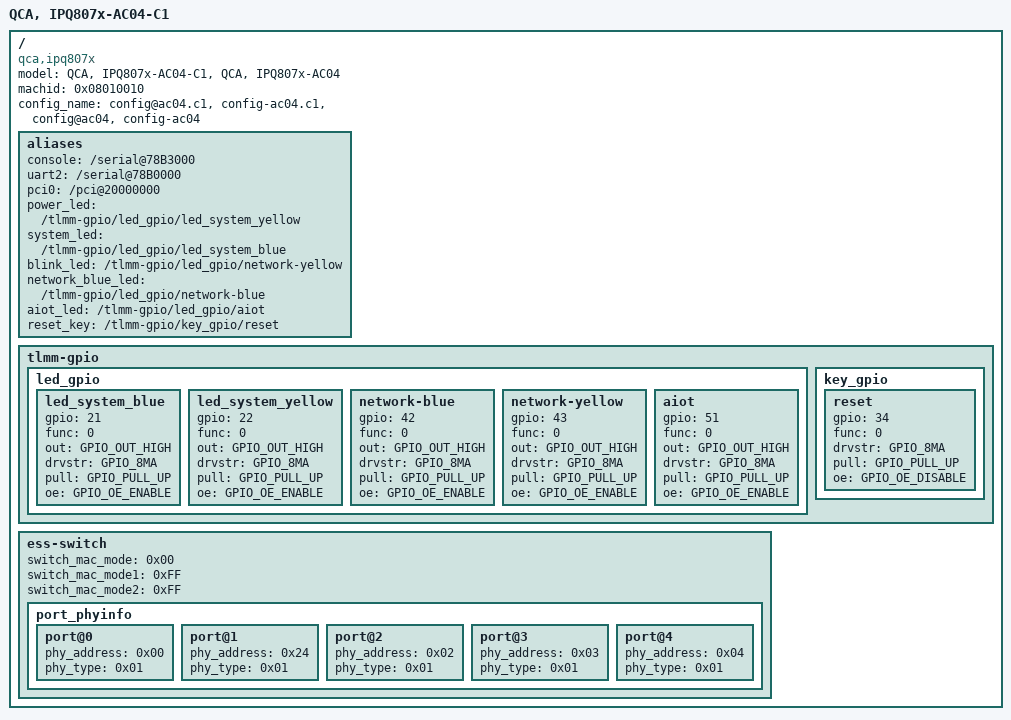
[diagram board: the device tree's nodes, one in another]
/*
 * Copyright (c) 2016 - 2018, The Linux Foundation. All rights reserved.
 *
 * This program is free software; you can redistribute it and/or modify
 * it under the terms of the GNU General Public License version 2 and
 * only version 2 as published by the Free Software Foundation.
 *
 * This program is distributed in the hope that it will be useful,
 * but WITHOUT ANY WARRANTY; without even the implied warranty of
 * MERCHANTABILITY or FITNESS FOR A PARTICULAR PURPOSE.  See the
 * GNU General Public License for more details.
 */

/dts-v1/;
#include "ipq807x-soc.dtsi"
#include <dt-bindings/qcom/gpio-ipq807x.h>
/ {
	model = "QCA, IPQ807x-AC04-C1", "QCA, IPQ807x-AC04";
	compatible = "qca,ipq807x", "qca,ipq807x-ac04-c1", "qca,ipq807x-ac04";
	machid = <0x08010010>;
	config_name = "config@ac04.c1", "config-ac04.c1", "config@ac04", "config-ac04";

	aliases {
		console = "/serial@78B3000";
		uart2 = "/serial@78B0000";
		pci0 = "/pci@20000000";
		power_led = "/tlmm-gpio/led_gpio/led_system_yellow";
		system_led = "/tlmm-gpio/led_gpio/led_system_blue";
		blink_led = "/tlmm-gpio/led_gpio/network-yellow";
		network_blue_led = "/tlmm-gpio/led_gpio/network-blue";
		aiot_led = "/tlmm-gpio/led_gpio/aiot";
		reset_key = "/tlmm-gpio/key_gpio/reset";
	};
	tlmm-gpio {
		led_gpio {
			led_system_blue {
				gpio = <21>;
				func = <0>;
				out = <GPIO_OUT_HIGH>;
				drvstr = <GPIO_8MA>;
				pull = <GPIO_PULL_UP>;
				oe = <GPIO_OE_ENABLE>;
			};
			led_system_yellow {
				gpio = <22>;
				func = <0>;
				out = <GPIO_OUT_HIGH>;
				drvstr = <GPIO_8MA>;
				pull = <GPIO_PULL_UP>;
				oe = <GPIO_OE_ENABLE>;
			};
			network-blue {
				gpio = <42>;
				func = <0>;
				out = <GPIO_OUT_HIGH>;
				drvstr = <GPIO_8MA>;
				pull = <GPIO_PULL_UP>;
				oe = <GPIO_OE_ENABLE>;
			};
			network-yellow {
				gpio = <43>;
				func = <0>;
				out = <GPIO_OUT_HIGH>;
				drvstr = <GPIO_8MA>;
				pull = <GPIO_PULL_UP>;
				oe = <GPIO_OE_ENABLE>;
			};
			aiot {
				gpio = <51>;
				func = <0>;
				out = <GPIO_OUT_HIGH>;
				drvstr = <GPIO_8MA>;
				pull = <GPIO_PULL_UP>;
				oe = <GPIO_OE_ENABLE>;
			};
		};
		key_gpio {
			reset {
				gpio = <34>;
				func = <0>;
				drvstr = <GPIO_8MA>;
				pull = <GPIO_PULL_UP>;
				oe = <GPIO_OE_DISABLE>;
			};
		};
	};
	ess-switch {
		switch_mac_mode = <0x00>;
		switch_mac_mode1 = <0xFF>;
		switch_mac_mode2 = <0xFF>;
		port_phyinfo {
			port@0 {
				phy_address = <0x00>;
				phy_type = <0x01>;
			};

			port@1 {
				phy_address = <0x24>;
				phy_type = <0x01>;
			};

			port@2 {
				phy_address = <0x02>;
				phy_type = <0x01>;
			};

			port@3 {
				phy_address = <0x03>;
				phy_type = <0x01>;
			};

			port@4 {
				phy_address = <0x04>;
				phy_type = <0x01>;
			};
		};
	};
};
